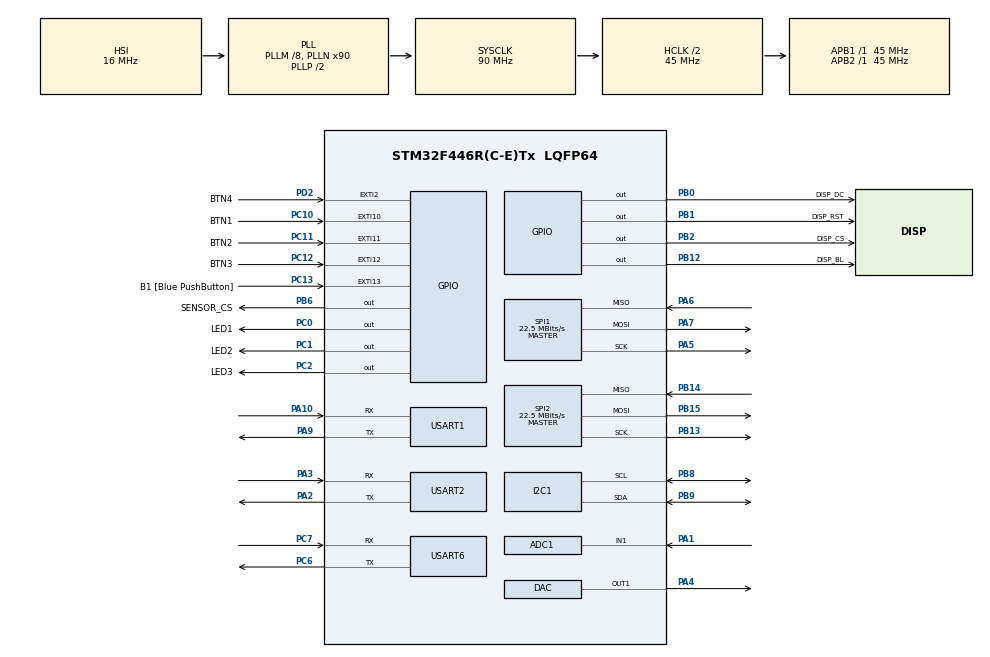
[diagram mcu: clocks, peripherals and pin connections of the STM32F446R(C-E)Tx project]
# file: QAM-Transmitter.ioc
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ADC1.Channel-0\#ChannelRegularConversion=ADC_CHANNEL_1
ADC1.NbrOfConversionFlag=1
ADC1.Rank-0\#ChannelRegularConversion=1
ADC1.SamplingTime-0\#ChannelRegularConversion=ADC_SAMPLETIME_3CYCLES
ADC1.master=1
Mcu.Family=STM32F4
Mcu.Name=STM32F446R(C-E)Tx
Mcu.Package=LQFP64
NVIC.PriorityGroup=NVIC_PRIORITYGROUP_4
NVIC.TIM6_DAC_IRQn=true\:0\:0\:false\:false\:true\:false\:true\:true
NVIC.TimeBase=TIM6_DAC_IRQn
NVIC.TimeBaseIP=TIM6
PA1.Signal=ADCx_IN1
PA10.Mode=Asynchronous
PA10.Signal=USART1_RX
PA13.GPIO_Label=TMS
PA13.Mode=Serial_Wire
PA13.Signal=SYS_JTMS-SWDIO
PA14.GPIO_Label=TCK
PA14.Mode=Serial_Wire
PA14.Signal=SYS_JTCK-SWCLK
PA2.Mode=Asynchronous
PA2.Signal=USART2_TX
PA3.Mode=Asynchronous
PA3.Signal=USART2_RX
PA4.Signal=COMP_DAC1_group
PA5.Mode=Full_Duplex_Master
PA5.Signal=SPI1_SCK
PA6.Mode=Full_Duplex_Master
PA6.Signal=SPI1_MISO
PA7.Mode=Full_Duplex_Master
PA7.Signal=SPI1_MOSI
PA9.Mode=Asynchronous
PA9.Signal=USART1_TX
PB0.GPIO_Label=DISP_DC
PB0.Signal=GPIO_Output
PB1.GPIO_Label=DISP_RST
PB1.Signal=GPIO_Output
PB12.GPIO_Label=DISP_BL
PB12.Signal=GPIO_Output
PB13.Mode=Full_Duplex_Master
PB13.Signal=SPI2_SCK
PB14.Mode=Full_Duplex_Master
PB14.Signal=SPI2_MISO
PB15.Mode=Full_Duplex_Master
PB15.Signal=SPI2_MOSI
PB2.GPIO_Label=DISP_CS
PB2.Signal=GPIO_Output
PB6.GPIO_Label=SENSOR_CS
PB6.Signal=GPIO_Output
PB8.Mode=I2C
PB8.Signal=I2C1_SCL
PB9.Mode=I2C
PB9.Signal=I2C1_SDA
PC0.GPIO_Label=LED1
PC0.Signal=GPIO_Output
PC1.GPIO_Label=LED2
PC1.Signal=GPIO_Output
PC10.GPIO_Label=BTN1
PC10.Signal=GPXTI10
PC11.GPIO_Label=BTN2
PC11.Signal=GPXTI11
PC12.GPIO_Label=BTN3
PC12.Signal=GPXTI12
PC13.GPIO_Label=B1 [Blue PushButton]
PC13.GPIO_ModeDefaultEXTI=GPIO_MODE_IT_FALLING
PC13.Signal=GPXTI13
PC2.GPIO_Label=LED3
PC2.Signal=GPIO_Output
PC6.Mode=Asynchronous
PC6.Signal=USART6_TX
PC7.Mode=Asynchronous
PC7.Signal=USART6_RX
PD2.GPIO_Label=BTN4
PD2.Signal=GPXTI2
ProjectManager.HeapSize=0x200
ProjectManager.StackSize=0x400
ProjectManager.TargetToolchain=STM32CubeIDE
RCC.48MHZClocksFreq_Value=84000000
RCC.AHBCLKDivider=RCC_SYSCLK_DIV2
RCC.AHBFreq_Value=45000000
RCC.APB1Freq_Value=45000000
RCC.APB1TimFreq_Value=45000000
RCC.APB2Freq_Value=45000000
RCC.APB2TimFreq_Value=45000000
RCC.CortexFreq_Value=45000000
RCC.FLatency-AdvancedSettings=FLASH_LATENCY_1
RCC.HCLKFreq_Value=45000000
RCC.HSE_VALUE=8000000
RCC.HSI_VALUE=16000000
RCC.PLLM=8
RCC.PLLN=90
RCC.SYSCLKFreq_VALUE=90000000
RCC.SYSCLKSource=RCC_SYSCLKSOURCE_PLLCLK
RCC.USBFreq_Value=90000000
RCC.VCOOutputFreq_Value=180000000
SH.ADCx_IN1.0=ADC1_IN1,IN1
SH.COMP_DAC1_group.0=DAC_OUT1,DAC_OUT1
SPI1.CalculateBaudRate=22.5 MBits/s
SPI1.Direction=SPI_DIRECTION_2LINES
SPI1.Mode=SPI_MODE_MASTER
SPI1.VirtualType=VM_MASTER
SPI2.BaudRatePrescaler=SPI_BAUDRATEPRESCALER_2
SPI2.CalculateBaudRate=22.5 MBits/s
SPI2.Direction=SPI_DIRECTION_2LINES
SPI2.Mode=SPI_MODE_MASTER
SPI2.VirtualType=VM_MASTER
USART1.VirtualMode=VM_ASYNC
USART2.VirtualMode=VM_ASYNC
USART6.VirtualMode=VM_ASYNC
VP_SYS_VS_tim6.Mode=TIM6
board=NUCLEO-F446RE

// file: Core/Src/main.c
/* USER CODE BEGIN Header */
/**
 ******************************************************************************
 * @file           : main.c
 * @brief          : Main program body
 ******************************************************************************
 * @attention
 *
 * Copyright (c) 2022 STMicroelectronics.
 * All rights reserved.
 *
 * This software is licensed under terms that can be found in the LICENSE file
 * in the root directory of this software component.
 * If no LICENSE file comes with this software, it is provided AS-IS.
 *
 ******************************************************************************
 */
/* USER CODE END Header */
#include "main.h"
#include "adc.h"
#include "dac.h"
#include "i2c.h"
#include "spi.h"
#include "usart.h"
#include "gpio.h"

void SystemClock_Config(void);

/* USER CODE BEGIN 0 */

/* GetIdleTaskMemory prototype (linked to static allocation support) */
void vApplicationGetIdleTaskMemory( StaticTask_t **ppxIdleTaskTCBBuffer, StackType_t **ppxIdleTaskStackBuffer, uint32_t *pulIdleTaskStackSize );

/* USER CODE BEGIN GET_IDLE_TASK_MEMORY */
static StaticTask_t xIdleTaskTCBBuffer;
static StackType_t xIdleStack[configMINIMAL_STACK_SIZE];

void vApplicationGetIdleTaskMemory( StaticTask_t **ppxIdleTaskTCBBuffer, StackType_t **ppxIdleTaskStackBuffer, uint32_t *pulIdleTaskStackSize )
{
  *ppxIdleTaskTCBBuffer = &xIdleTaskTCBBuffer;
  *ppxIdleTaskStackBuffer = &xIdleStack[0];
  *pulIdleTaskStackSize = configMINIMAL_STACK_SIZE;
  /* place for user code */
}

/* USER CODE END 0 */

int main(void)
{

  /* MCU Configuration--------------------------------------------------------*/

  /* Reset of all peripherals, Initializes the Flash interface and the Systick. */
  HAL_Init();

  /* Configure the system clock */
  SystemClock_Config();

  /* Initialize all configured peripherals */
  MX_GPIO_Init();
  MX_USART2_UART_Init();
  MX_ADC1_Init();
  MX_DAC_Init();
  MX_I2C1_Init();
  MX_SPI1_Init();
  MX_SPI2_Init();
  MX_USART1_UART_Init();
  MX_USART6_UART_Init();
  /* USER CODE BEGIN 2 */

  /* Start scheduler */
  /* We should never get here as control is now taken by the scheduler */
  vTaskStartScheduler();

  /* USER CODE END 2 */

  /* Infinite loop */
	while( 1 )
	{

	}
}

void SystemClock_Config(void)
{
  RCC_OscInitTypeDef RCC_OscInitStruct = {0};
  RCC_ClkInitTypeDef RCC_ClkInitStruct = {0};

  /** Configure the main internal regulator output voltage
  */
  __HAL_RCC_PWR_CLK_ENABLE();
  __HAL_PWR_VOLTAGESCALING_CONFIG(PWR_REGULATOR_VOLTAGE_SCALE3);

  /** Initializes the RCC Oscillators according to the specified parameters
  * in the RCC_OscInitTypeDef structure.
  */
  RCC_OscInitStruct.OscillatorType = RCC_OSCILLATORTYPE_HSI;
  RCC_OscInitStruct.HSIState = RCC_HSI_ON;
  RCC_OscInitStruct.HSICalibrationValue = RCC_HSICALIBRATION_DEFAULT;
  RCC_OscInitStruct.PLL.PLLState = RCC_PLL_ON;
  RCC_OscInitStruct.PLL.PLLSource = RCC_PLLSOURCE_HSI;
  RCC_OscInitStruct.PLL.PLLM = 8;
  RCC_OscInitStruct.PLL.PLLN = 90;
  RCC_OscInitStruct.PLL.PLLP = RCC_PLLP_DIV2;
  RCC_OscInitStruct.PLL.PLLQ = 2;
  RCC_OscInitStruct.PLL.PLLR = 2;
  if (HAL_RCC_OscConfig(&RCC_OscInitStruct) != HAL_OK)
  {
    Error_Handler();
  }

  /** Initializes the CPU, AHB and APB buses clocks
  */
  RCC_ClkInitStruct.ClockType = RCC_CLOCKTYPE_HCLK|RCC_CLOCKTYPE_SYSCLK
                              |RCC_CLOCKTYPE_PCLK1|RCC_CLOCKTYPE_PCLK2;
  RCC_ClkInitStruct.SYSCLKSource = RCC_SYSCLKSOURCE_PLLCLK;
  RCC_ClkInitStruct.AHBCLKDivider = RCC_SYSCLK_DIV2;
  RCC_ClkInitStruct.APB1CLKDivider = RCC_HCLK_DIV1;
  RCC_ClkInitStruct.APB2CLKDivider = RCC_HCLK_DIV1;

  if (HAL_RCC_ClockConfig(&RCC_ClkInitStruct, FLASH_LATENCY_1) != HAL_OK)
  {
    Error_Handler();
  }
}

void HAL_TIM_PeriodElapsedCallback(TIM_HandleTypeDef *htim)
{
  if (htim->Instance == TIM6) {
    HAL_IncTick();
  }
}

void Error_Handler(void)
{
  /* USER CODE BEGIN Error_Handler_Debug */
	/* User can add his own implementation to report the HAL error return state */
	__disable_irq( );
	while( 1 )
	{
	}
  /* USER CODE END Error_Handler_Debug */
}
